AUTOSAR XML (schema 00050)
package /FCADT/ComponentTypes
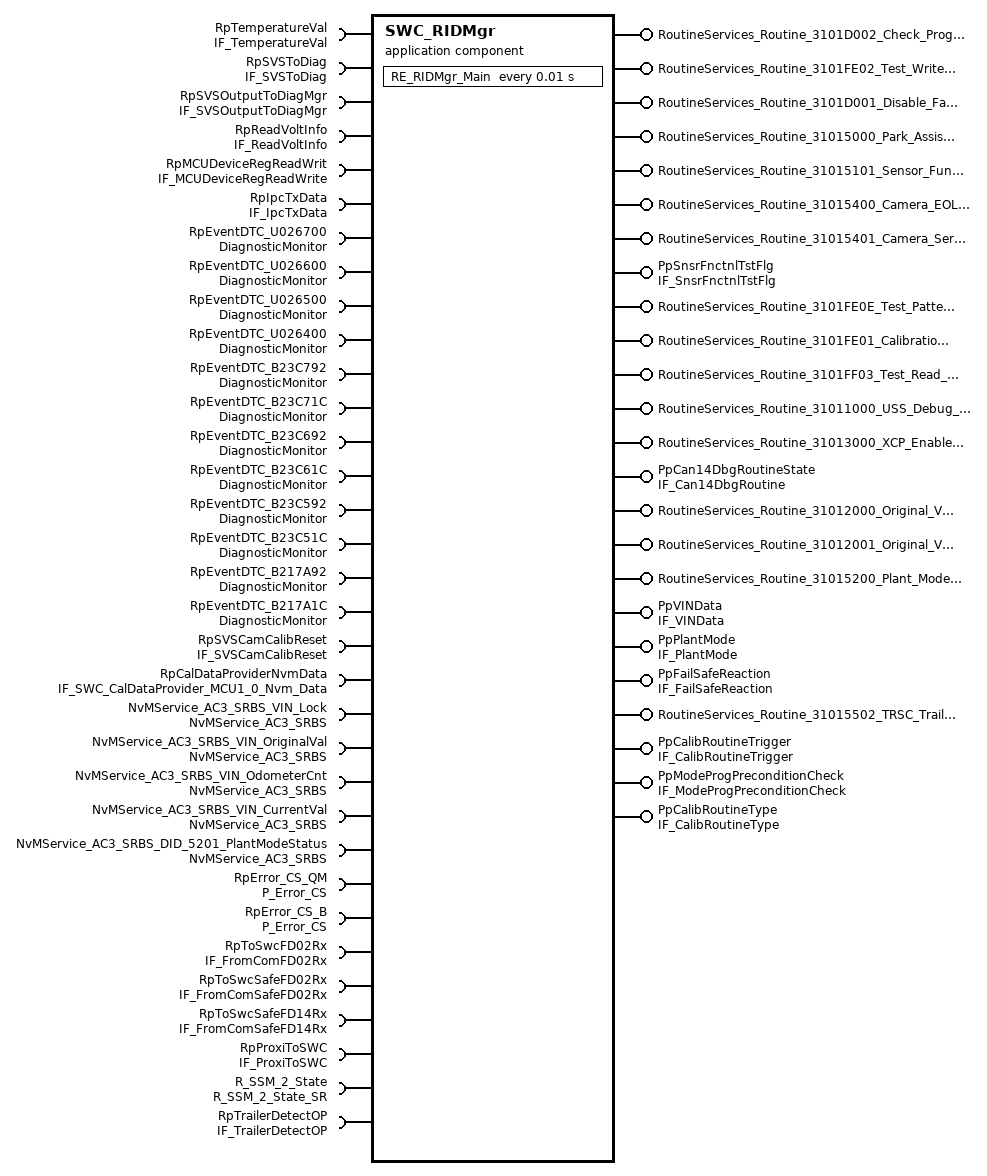
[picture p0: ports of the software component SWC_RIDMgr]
  application sw component type SWC_RIDMgr
    10 x provide port:
      RoutineServices_Routine_3101D002_Check_Programming_Preconditions_Start: server-com-spec{operation=Start, queue-length=1}, provided-interface=RoutineServices_Routine_3101D002_Check_Programming_Preconditions_Start
      RoutineServices_Routine_3101FE02_Test_Write_PMIC_Register_Start: server-com-spec{operation=Start, queue-length=1}, provided-interface=RoutineServices_Routine_3101FE02_Test_Write_PMIC_Register_Start
      RoutineServices_Routine_3101D001_Disable_Fail_safe_reaction_Start: provided-com-specs=[{operation=Start, queue-length=1}, {operation=Stop, queue-length=1}], provided-interface=RoutineServices_Routine_3101D001_Disable_Fail_safe_reaction_Start
      RoutineServices_Routine_31015000_Park_Assist_ON_OFF_State_Start: server-com-spec{operation=Start, queue-length=1}, provided-interface=RoutineServices_Routine_31015000_Park_Assist_ON_OFF_State_Start
      RoutineServices_Routine_31015101_Sensor_Functional_Test_Start: server-com-spec{operation=Start, queue-length=1}, provided-interface=RoutineServices_Routine_31015101_Sensor_Functional_Test_Start
      RoutineServices_Routine_31015400_Camera_EOL_Calibration_Start: provided-com-specs=[{operation=Start, queue-length=1}, {operation=RequestResults, queue-length=1}], provided-interface=RoutineServices_Routine_31015400_Camera_EOL_Calibration_Start
      RoutineServices_Routine_31015401_Camera_Service_Calibration_Start: provided-com-specs=[{operation=Start, queue-length=1}, {operation=RequestResults, queue-length=1}], provided-interface=RoutineServices_Routine_31015401_Camera_Service_Calibration_Start
      PpSnsrFnctnlTstFlg: nonqueued-sender-com-spec{data-element=SensorFunctionalTestFlag, init-value=constant-reference=init_SensorFunctionalTestFlag}, provided-interface=IF_SnsrFnctnlTstFlg
      RoutineServices_Routine_3101FE0E_Test_Pattern_Control_Start: provided-com-specs=[{operation=Stop, queue-length=1}, {operation=Start, queue-length=1}], provided-interface=RoutineServices_Routine_3101FE0E_Test_Pattern_Control_Start
      RoutineServices_Routine_3101FE01_Calibration_Data_Reset_Start: server-com-spec{operation=Start, queue-length=1}, provided-interface=RoutineServices_Routine_3101FE01_Calibration_Data_Reset_Start
    18 x require port:
      RpTemperatureVal: nonqueued-receiver-com-spec{data-element=GetTemperatureVal, filter=data-filter-type=ALWAYS}, required-interface=IF_TemperatureVal
      RpSVSToDiag: nonqueued-receiver-com-spec{data-element=SVSToDiag_t, filter=data-filter-type=ALWAYS}, required-interface=IF_SVSToDiag
      RpSVSOutputToDiagMgr: nonqueued-receiver-com-spec{data-element=TbSVS_e_SVSOutputToDiagMgrCamCalib_t, filter=data-filter-type=ALWAYS}, required-interface=IF_SVSOutputToDiagMgr
      RpReadVoltInfo: client-com-spec=GetVoltageInfo, required-interface=IF_ReadVoltInfo
      RpMCUDeviceRegReadWrit: required-com-specs=[MCUWriteDeviceReg, MCUReadDeviceRegData, MCUReadDeviceReg], required-interface=IF_MCUDeviceRegReadWrite
      RpIpcTxData: client-com-spec=IPC_Write_v, required-interface=IF_IpcTxData
      RpEventDTC_U026700: required-interface=DiagnosticMonitor
        required-com-specs:
          GetEventExtendedDataRecordEx
          GetEventFreezeFrameDataEx
          GetFaultDetectionCounter
          GetDTCOfEvent
          GetEventTested
          GetEventFailed
          GetEventStatus
          GetEventUdsStatus
          ResetEventDebounceStatus
          ResetEventStatus
          SetEventStatus
      RpEventDTC_U026600: required-interface=DiagnosticMonitor
        required-com-specs:
          GetEventExtendedDataRecordEx
          GetEventFreezeFrameDataEx
          GetFaultDetectionCounter
          GetDTCOfEvent
          GetEventTested
          GetEventFailed
          GetEventStatus
          GetEventUdsStatus
          ResetEventDebounceStatus
          ResetEventStatus
          SetEventStatus
      RpEventDTC_U026500: required-interface=DiagnosticMonitor
        required-com-specs:
          GetEventExtendedDataRecordEx
          GetEventFreezeFrameDataEx
          GetFaultDetectionCounter
          GetDTCOfEvent
          GetEventTested
          GetEventFailed
          GetEventStatus
          GetEventUdsStatus
          ResetEventDebounceStatus
          ResetEventStatus
          SetEventStatus
      RpEventDTC_U026400: required-interface=DiagnosticMonitor
        required-com-specs:
          GetEventExtendedDataRecordEx
          GetEventFreezeFrameDataEx
          GetFaultDetectionCounter
          GetDTCOfEvent
          GetEventTested
          GetEventFailed
          GetEventStatus
          GetEventUdsStatus
          ResetEventDebounceStatus
          ResetEventStatus
          SetEventStatus
      RpEventDTC_B23C792: required-interface=DiagnosticMonitor
        required-com-specs:
          GetEventExtendedDataRecordEx
          GetEventFreezeFrameDataEx
          GetFaultDetectionCounter
          GetDTCOfEvent
          GetEventTested
          GetEventFailed
          GetEventStatus
          GetEventUdsStatus
          ResetEventDebounceStatus
          ResetEventStatus
          SetEventStatus
      RpEventDTC_B23C71C: required-interface=DiagnosticMonitor
        required-com-specs:
          GetEventExtendedDataRecordEx
          GetEventFreezeFrameDataEx
          GetFaultDetectionCounter
          GetDTCOfEvent
          GetEventTested
          GetEventFailed
          GetEventStatus
          GetEventUdsStatus
          ResetEventDebounceStatus
          ResetEventStatus
          SetEventStatus
      RpEventDTC_B23C692: required-interface=DiagnosticMonitor
        required-com-specs:
          GetEventExtendedDataRecordEx
          GetEventFreezeFrameDataEx
          GetFaultDetectionCounter
          GetDTCOfEvent
          GetEventTested
          GetEventFailed
          GetEventStatus
          GetEventUdsStatus
          ResetEventDebounceStatus
          ResetEventStatus
          SetEventStatus
      RpEventDTC_B23C61C: required-interface=DiagnosticMonitor
        required-com-specs:
          GetEventExtendedDataRecordEx
          GetEventFreezeFrameDataEx
          GetFaultDetectionCounter
          GetDTCOfEvent
          GetEventTested
          GetEventFailed
          GetEventStatus
          GetEventUdsStatus
          ResetEventDebounceStatus
          ResetEventStatus
          SetEventStatus
      RpEventDTC_B23C592: required-interface=DiagnosticMonitor
        required-com-specs:
          GetEventExtendedDataRecordEx
          GetEventFreezeFrameDataEx
          GetFaultDetectionCounter
          GetDTCOfEvent
          GetEventTested
          GetEventFailed
          GetEventStatus
          GetEventUdsStatus
          ResetEventDebounceStatus
          ResetEventStatus
          SetEventStatus
      RpEventDTC_B23C51C: required-interface=DiagnosticMonitor
        required-com-specs:
          GetEventExtendedDataRecordEx
          GetEventFreezeFrameDataEx
          GetFaultDetectionCounter
          GetDTCOfEvent
          GetEventTested
          GetEventFailed
          GetEventStatus
          GetEventUdsStatus
          ResetEventDebounceStatus
          ResetEventStatus
          SetEventStatus
      RpEventDTC_B217A92: required-interface=DiagnosticMonitor
        required-com-specs:
          GetEventExtendedDataRecordEx
          GetEventFreezeFrameDataEx
          GetFaultDetectionCounter
          GetDTCOfEvent
          GetEventTested
          GetEventFailed
          GetEventStatus
          GetEventUdsStatus
          ResetEventDebounceStatus
          ResetEventStatus
          SetEventStatus
      RpEventDTC_B217A1C: required-interface=DiagnosticMonitor
        required-com-specs:
          GetEventExtendedDataRecordEx
          GetEventFreezeFrameDataEx
          GetFaultDetectionCounter
          GetDTCOfEvent
          GetEventTested
          GetEventFailed
          GetEventStatus
          GetEventUdsStatus
          ResetEventDebounceStatus
          ResetEventStatus
          SetEventStatus
    provide port RoutineServices_Routine_3101FF03_Test_Read_PMIC_Register_Start: server-com-spec{operation=Start, queue-length=1}, provided-interface=RoutineServices_Routine_3101FF03_Test_Read_PMIC_Register_Start
    require port RpSVSCamCalibReset: client-com-spec=WriteBlock, required-interface=IF_SVSCamCalibReset
    require port RpCalDataProviderNvmData: nonqueued-receiver-com-spec{data-element=CalData_mcu1_0, filter=data-filter-type=ALWAYS}, required-interface=IF_SWC_CalDataProvider_MCU1_0_Nvm_Data
    6 x provide port:
      RoutineServices_Routine_31011000_USS_Debug_Signals_Enable_Disable_Start: server-com-spec{operation=Start, queue-length=1}, provided-interface=RoutineServices_Routine_31011000_USS_Debug_Signals_Enable_Disable_Start
      RoutineServices_Routine_31013000_XCP_Enable_Disable_Start: server-com-spec{operation=Start, queue-length=1}, provided-interface=RoutineServices_Routine_31013000_XCP_Enable_Disable_Start
      PpCan14DbgRoutineState: nonqueued-sender-com-spec{data-element=Can14DbgRoutine, init-value=0}, provided-interface=IF_Can14DbgRoutine
      RoutineServices_Routine_31012000_Original_VIN_Lock: server-com-spec{operation=Start, queue-length=1}, provided-interface=RoutineServices_Routine_31012000_Original_VIN_Lock
      RoutineServices_Routine_31012001_Original_VIN_Unlock: server-com-spec{operation=Start, queue-length=1}, provided-interface=RoutineServices_Routine_31012001_Original_VIN_Unlock
      RoutineServices_Routine_31015200_Plant_Mode_Routine_Start: provided-com-specs=[{operation=RequestResults, queue-length=1}, {operation=Start, queue-length=1}], provided-interface=RoutineServices_Routine_31015200_Plant_Mode_Routine_Start
    5 x require port, all with required-com-specs=[WriteBlock, SetRamBlockStatus, ReadBlock, InvalidateNvBlock, GetErrorStatus, EraseBlock], required-interface=NvMService_AC3_SRBS:
      NvMService_AC3_SRBS_VIN_Lock
      NvMService_AC3_SRBS_VIN_OriginalVal
      NvMService_AC3_SRBS_VIN_OdometerCnt
      NvMService_AC3_SRBS_VIN_CurrentVal
      NvMService_AC3_SRBS_DID_5201_PlantModeStatus
    provide port PpVINData: provided-com-specs=[VINOriginalData, VINCurrentData, VINOdoCounter, VINLockStatus], provided-interface=IF_VINData
    require port RpError_CS_QM: client-com-spec=ReportErrorStatus1_0_QM, required-interface=P_Error_CS
    require port RpError_CS_B: client-com-spec=ReportErrorStatus1_0_B, required-interface=P_Error_CS
    provide port PpPlantMode: nonqueued-sender-com-spec{data-element=Status, init-value=0}, provided-interface=IF_PlantMode
    require port RpToSwcFD02Rx: required-interface=IF_FromComFD02Rx
      required-com-specs:
        data-element=Altitude_RMSE_C2, filter=data-filter-type=ALWAYS, init-value=255
        data-element=Battery_Volt_1, filter=data-filter-type=ALWAYS, init-value=0
        data-element=BSM_THA_Brk_Resp, filter=data-filter-type=ALWAYS, init-value=0
        data-element=CurrentCanNMState_FD01_BCM, filter=data-filter-type=ALWAYS, init-value=0
        data-element=CurrentCanNMState_FD01_SGW, filter=data-filter-type=ALWAYS, init-value=0
        data-element=CurrentCanNMState_FD02_BCM, filter=data-filter-type=ALWAYS, init-value=0
        data-element=CurrentCanNMState_FD02_BSM2, filter=data-filter-type=ALWAYS, init-value=0
        data-element=CurrentCanNMState_FD02_CADM2, filter=data-filter-type=ALWAYS, init-value=0
        data-element=CurrentCanNMState_FD02_EPS, filter=data-filter-type=ALWAYS, init-value=0
        data-element=CurrentCanNMState_FD02_ORC, filter=data-filter-type=ALWAYS, init-value=0
        data-element=CurrentCanNMState_FD02_SGW, filter=data-filter-type=ALWAYS, init-value=0
        data-element=CurrentCanNMState_FD02_TRLR_REV, filter=data-filter-type=ALWAYS, init-value=0
        data-element=CurrentCanNMState_FD03_BCM, filter=data-filter-type=ALWAYS, init-value=0
        data-element=CurrentCanNMState_FD03_SGW, filter=data-filter-type=ALWAYS, init-value=0
        data-element=CurrentCanNMState_FD04_BCM, filter=data-filter-type=ALWAYS, init-value=0
        data-element=CurrentCanNMState_FD08_SGW, filter=data-filter-type=ALWAYS, init-value=0
        data-element=CurrentCanNMState_FD11_SGW, filter=data-filter-type=ALWAYS, init-value=0
        data-element=CurrentFailSts_FD01_BCM, filter=data-filter-type=ALWAYS, init-value=0
        data-element=CurrentFailSts_FD01_SGW, filter=data-filter-type=ALWAYS, init-value=0
        data-element=CurrentFailSts_FD02_BCM, filter=data-filter-type=ALWAYS, init-value=0
        data-element=CurrentFailSts_FD02_BSM2, filter=data-filter-type=ALWAYS, init-value=0
        data-element=CurrentFailSts_FD02_CADM2, filter=data-filter-type=ALWAYS, init-value=0
        data-element=CurrentFailSts_FD02_EPS, filter=data-filter-type=ALWAYS, init-value=0
        data-element=CurrentFailSts_FD02_ORC, filter=data-filter-type=ALWAYS, init-value=0
        data-element=CurrentFailSts_FD02_SGW, filter=data-filter-type=ALWAYS, init-value=0
        data-element=CurrentFailSts_FD02_TRLR_REV, filter=data-filter-type=ALWAYS, init-value=0
        data-element=CurrentFailSts_FD03_BCM, filter=data-filter-type=ALWAYS, init-value=0
        data-element=CurrentFailSts_FD03_SGW, filter=data-filter-type=ALWAYS, init-value=0
        data-element=CurrentFailSts_FD04_BCM, filter=data-filter-type=ALWAYS, init-value=0
        data-element=CurrentFailSts_FD08_SGW, filter=data-filter-type=ALWAYS, init-value=0
        data-element=CurrentFailSts_FD11_SGW, filter=data-filter-type=ALWAYS, init-value=0
        data-element=DeltaTimestamp_IMUdata, filter=data-filter-type=ALWAYS, init-value=255
        data-element=DES_FD01_BCM, filter=data-filter-type=ALWAYS, init-value=0
        data-element=DES_FD01_SGW, filter=data-filter-type=ALWAYS, init-value=0
        data-element=DES_FD02_BCM, filter=data-filter-type=ALWAYS, init-value=0
        data-element=DES_FD02_BSM2, filter=data-filter-type=ALWAYS, init-value=0
        data-element=DES_FD02_CADM2, filter=data-filter-type=ALWAYS, init-value=0
        data-element=DES_FD02_EPS, filter=data-filter-type=ALWAYS, init-value=0
        data-element=DES_FD02_ORC, filter=data-filter-type=ALWAYS, init-value=0
        data-element=DES_FD02_SGW, filter=data-filter-type=ALWAYS, init-value=0
        data-element=DES_FD02_TRLR_REV, filter=data-filter-type=ALWAYS, init-value=0
        data-element=DES_FD03_BCM, filter=data-filter-type=ALWAYS, init-value=0
        data-element=DES_FD03_SGW, filter=data-filter-type=ALWAYS, init-value=0
        data-element=DES_FD04_BCM, filter=data-filter-type=ALWAYS, init-value=0
        data-element=DES_FD08_SGW, filter=data-filter-type=ALWAYS, init-value=0
        data-element=DES_FD11_SGW, filter=data-filter-type=ALWAYS, init-value=0
        data-element=Digit_{01..11}, filter=data-filter-type=ALWAYS, init-value=0
        data-element=EOL_FD01_BCM, filter=data-filter-type=ALWAYS, init-value=0
        data-element=EOL_FD01_SGW, filter=data-filter-type=ALWAYS, init-value=0
        data-element=EOL_FD02_BCM, filter=data-filter-type=ALWAYS, init-value=0
        data-element=EOL_FD02_BSM2, filter=data-filter-type=ALWAYS, init-value=0
        data-element=EOL_FD02_CADM2, filter=data-filter-type=ALWAYS, init-value=0
        data-element=EOL_FD02_EPS, filter=data-filter-type=ALWAYS, init-value=0
        data-element=EOL_FD02_ORC, filter=data-filter-type=ALWAYS, init-value=0
        data-element=EOL_FD02_SGW, filter=data-filter-type=ALWAYS, init-value=0
        data-element=EOL_FD02_TRLR_REV, filter=data-filter-type=ALWAYS, init-value=0
        data-element=EOL_FD03_BCM, filter=data-filter-type=ALWAYS, init-value=0
        data-element=EOL_FD03_SGW, filter=data-filter-type=ALWAYS, init-value=0
        data-element=EOL_FD04_BCM, filter=data-filter-type=ALWAYS, init-value=0
        data-element=EOL_FD08_SGW, filter=data-filter-type=ALWAYS, init-value=0
        data-element=EOL_FD11_SGW, filter=data-filter-type=ALWAYS, init-value=0
        data-element=EPBSts, filter=data-filter-type=ALWAYS, init-value=0
        data-element=GenericFailSts_FD01_BCM, filter=data-filter-type=ALWAYS, init-value=0
        data-element=GenericFailSts_FD01_SGW, filter=data-filter-type=ALWAYS, init-value=0
        data-element=GenericFailSts_FD02_BCM, filter=data-filter-type=ALWAYS, init-value=0
        data-element=GenericFailSts_FD02_BSM2, filter=data-filter-type=ALWAYS, init-value=0
        data-element=GenericFailSts_FD02_CADM2, filter=data-filter-type=ALWAYS, init-value=0
        data-element=GenericFailSts_FD02_EPS, filter=data-filter-type=ALWAYS, init-value=0
        data-element=GenericFailSts_FD02_ORC, filter=data-filter-type=ALWAYS, init-value=0
        data-element=GenericFailSts_FD02_SGW, filter=data-filter-type=ALWAYS, init-value=0
        data-element=GenericFailSts_FD02_TRLR_REV, filter=data-filter-type=ALWAYS, init-value=0
        data-element=GenericFailSts_FD03_BCM, filter=data-filter-type=ALWAYS, init-value=0
        data-element=GenericFailSts_FD03_SGW, filter=data-filter-type=ALWAYS, init-value=0
        data-element=GenericFailSts_FD04_BCM, filter=data-filter-type=ALWAYS, init-value=0
        data-element=GenericFailSts_FD08_SGW, filter=data-filter-type=ALWAYS, init-value=0
        data-element=GenericFailSts_FD11_SGW, filter=data-filter-type=ALWAYS, init-value=0
        data-element=Heading_Angle_C2, filter=data-filter-type=ALWAYS, init-value=65535
        data-element=IgnitionOnCounter, filter=data-filter-type=ALWAYS, init-value=0
        data-element=LatAcceleration_C2, filter=data-filter-type=ALWAYS, init-value=4095
        data-element=LatAccelerationOffset_BSM, filter=data-filter-type=ALWAYS, init-value=255
        data-element=Latitude_RMSE_C2, filter=data-filter-type=ALWAYS, init-value=255
        data-element=LHF_FastPulseCounter, filter=data-filter-type=ALWAYS, init-value=0
        data-element=LHF_Spin, filter=data-filter-type=ALWAYS, init-value=0
        data-element=LHFWheelSpeed, filter=data-filter-type=ALWAYS, init-value=0
        data-element=LHR_FastPulseCounter, filter=data-filter-type=ALWAYS, init-value=0
        data-element=LHR_Spin, filter=data-filter-type=ALWAYS, init-value=0
        data-element=LHRWheelSpeed, filter=data-filter-type=ALWAYS, init-value=0
        data-element=LongAcceleration_C2, filter=data-filter-type=ALWAYS, init-value=4095
        data-element=LongAccelerationOffset_BSM, filter=data-filter-type=ALWAYS, init-value=255
        data-element=Longitude_RMSE_C2, filter=data-filter-type=ALWAYS, init-value=255
        data-element=OperationalModeSts, filter=data-filter-type=ALWAYS, init-value=0
        data-element=Pitch_RMSE_C2, filter=data-filter-type=ALWAYS, init-value=255
        data-element=PitchRate_C2, filter=data-filter-type=ALWAYS, init-value=4095
        data-element=PreviousCanNMState_FD01_BCM, filter=data-filter-type=ALWAYS, init-value=0
        data-element=PreviousCanNMState_FD01_SGW, filter=data-filter-type=ALWAYS, init-value=0
        data-element=PreviousCanNMState_FD02_BCM, filter=data-filter-type=ALWAYS, init-value=0
        data-element=PreviousCanNMState_FD02_BSM2, filter=data-filter-type=ALWAYS, init-value=0
        data-element=PreviousCanNMState_FD02_CADM2, filter=data-filter-type=ALWAYS, init-value=0
        data-element=PreviousCanNMState_FD02_EPS, filter=data-filter-type=ALWAYS, init-value=0
        data-element=PreviousCanNMState_FD02_ORC, filter=data-filter-type=ALWAYS, init-value=0
        data-element=PreviousCanNMState_FD02_SGW, filter=data-filter-type=ALWAYS, init-value=0
        data-element=PreviousCanNMState_FD02_TRLR_REV, filter=data-filter-type=ALWAYS, init-value=0
        data-element=PreviousCanNMState_FD03_BCM, filter=data-filter-type=ALWAYS, init-value=0
        data-element=PreviousCanNMState_FD03_SGW, filter=data-filter-type=ALWAYS, init-value=0
        data-element=PreviousCanNMState_FD04_BCM, filter=data-filter-type=ALWAYS, init-value=0
        data-element=PreviousCanNMState_FD08_SGW, filter=data-filter-type=ALWAYS, init-value=0
        data-element=PreviousCanNMState_FD11_SGW, filter=data-filter-type=ALWAYS, init-value=0
        data-element=REF_VEH_SPEED, filter=data-filter-type=ALWAYS, init-value=1023
        data-element=RemStActvSts, filter=data-filter-type=ALWAYS, init-value=0
        data-element=RHF_FastPulseCounter, filter=data-filter-type=ALWAYS, init-value=0
        data-element=RHF_Spin, filter=data-filter-type=ALWAYS, init-value=0
        data-element=RHFWheelSpeed, filter=data-filter-type=ALWAYS, init-value=0
        data-element=RHR_FastPulseCounter, filter=data-filter-type=ALWAYS, init-value=0
        data-element=RHR_Spin, filter=data-filter-type=ALWAYS, init-value=0
        data-element=RHRWheelSpeed, filter=data-filter-type=ALWAYS, init-value=0
        data-element=Roll_RMSE_C2, filter=data-filter-type=ALWAYS, init-value=255
        data-element=RollRate_C2, filter=data-filter-type=ALWAYS, init-value=4095
        data-element=SBR1RowDriverSeatSts, filter=data-filter-type=ALWAYS, init-value=3
        data-element=StayActiveSource_FD01_BCM, filter=data-filter-type=ALWAYS, init-value=0
        data-element=StayActiveSource_FD01_SGW, filter=data-filter-type=ALWAYS, init-value=0
        data-element=StayActiveSource_FD02_BCM, filter=data-filter-type=ALWAYS, init-value=0
        data-element=StayActiveSource_FD02_BSM2, filter=data-filter-type=ALWAYS, init-value=0
        data-element=StayActiveSource_FD02_CADM2, filter=data-filter-type=ALWAYS, init-value=0
        data-element=StayActiveSource_FD02_EPS, filter=data-filter-type=ALWAYS, init-value=0
        data-element=StayActiveSource_FD02_ORC, filter=data-filter-type=ALWAYS, init-value=0
        data-element=StayActiveSource_FD02_SGW, filter=data-filter-type=ALWAYS, init-value=0
        data-element=StayActiveSource_FD02_TRLR_REV, filter=data-filter-type=ALWAYS, init-value=0
        data-element=StayActiveSource_FD03_BCM, filter=data-filter-type=ALWAYS, init-value=0
        data-element=StayActiveSource_FD03_SGW, filter=data-filter-type=ALWAYS, init-value=0
        data-element=StayActiveSource_FD04_BCM, filter=data-filter-type=ALWAYS, init-value=0
        data-element=StayActiveSource_FD08_SGW, filter=data-filter-type=ALWAYS, init-value=0
        data-element=StayActiveSource_FD11_SGW, filter=data-filter-type=ALWAYS, init-value=0
        data-element=TotalOdometer, filter=data-filter-type=ALWAYS, init-value=0
        data-element=TRSC_CenterBtn_Sts, filter=data-filter-type=ALWAYS, init-value=0
        data-element=TRSC_EnableBtn_Sts, filter=data-filter-type=ALWAYS, init-value=0
        data-element=TRSC_RawKnob, filter=data-filter-type=ALWAYS, init-value=0
        data-element=TurnIndicatorSts, filter=data-filter-type=ALWAYS, init-value=0
        data-element=VehicleStandStillSts, filter=data-filter-type=ALWAYS, init-value=1
        data-element=VerticalAcceleration_C2, filter=data-filter-type=ALWAYS, init-value=4095
        data-element=WakeupSource_FD01_ADCM, filter=data-filter-type=ALWAYS, init-value=0
        data-element=WakeupSource_FD01_BCM, filter=data-filter-type=ALWAYS, init-value=0
        data-element=WakeupSource_FD01_SGW, filter=data-filter-type=ALWAYS, init-value=0
        data-element=WakeupSource_FD02_BCM, filter=data-filter-type=ALWAYS, init-value=0
        data-element=WakeupSource_FD02_BSM2, filter=data-filter-type=ALWAYS, init-value=0
        data-element=WakeupSource_FD02_CADM2, filter=data-filter-type=ALWAYS, init-value=0
        data-element=WakeupSource_FD02_EPS, filter=data-filter-type=ALWAYS, init-value=0
        data-element=WakeupSource_FD02_ORC, filter=data-filter-type=ALWAYS, init-value=0
        data-element=WakeupSource_FD02_SGW, filter=data-filter-type=ALWAYS, init-value=0
        data-element=WakeupSource_FD02_TRLR_REV, filter=data-filter-type=ALWAYS, init-value=0
        data-element=WakeupSource_FD03_BCM, filter=data-filter-type=ALWAYS, init-value=0
        data-element=WakeupSource_FD03_SGW, filter=data-filter-type=ALWAYS, init-value=0
        data-element=WakeupSource_FD04_BCM, filter=data-filter-type=ALWAYS, init-value=0
        data-element=WakeupSource_FD08_SGW, filter=data-filter-type=ALWAYS, init-value=0
        data-element=WakeupSource_FD11_SGW, filter=data-filter-type=ALWAYS, init-value=0
        data-element=YawRate_C2, filter=data-filter-type=ALWAYS, init-value=4095
        data-element=YawRate_RMSE_C2, filter=data-filter-type=ALWAYS, init-value=255
    require port RpToSwcSafeFD02Rx: required-interface=IF_FromComSafeFD02Rx
      required-com-specs:
        data-element=Active_Park_Mode, filter=data-filter-type=ALWAYS, init-value=0
        data-element=Active_Park_Prox_Chime, filter=data-filter-type=ALWAYS, init-value=0
        data-element=APARequestSts, filter=data-filter-type=ALWAYS, init-value=0
        data-element=Backup_Cam_Delay, filter=data-filter-type=ALWAYS, init-value=0
        data-element=Brk_Stat, filter=data-filter-type=ALWAYS, init-value=0
        data-element=CmdIgnSts, filter=data-filter-type=ALWAYS, init-value=0
        data-element=DriverDoorSts, filter=data-filter-type=ALWAYS, init-value=0
        data-element=DynamicGrid, filter=data-filter-type=ALWAYS, init-value=1
        data-element=ExternalTemperature, filter=data-filter-type=ALWAYS, init-value=0
        data-element=FT_PAMRequestSts, filter=data-filter-type=ALWAYS, init-value=0
        data-element=Fwrd_Cam_Guidelines, filter=data-filter-type=ALWAYS, init-value=0
        data-element=GearEngaged, filter=data-filter-type=ALWAYS, init-value=0
        data-element=HAS_Status_C2, filter=data-filter-type=ALWAYS, init-value=0
        data-element=LanguageSelection, filter=data-filter-type=ALWAYS, init-value=0
        data-element=LatAcceleration_BSM, filter=data-filter-type=ALWAYS, init-value=4095
        data-element=LHRDoorSts, filter=data-filter-type=ALWAYS, init-value=0
        data-element=LongAcceleration_BSM, filter=data-filter-type=ALWAYS, init-value=4095
        data-element=LwsAngle, filter=data-filter-type=ALWAYS, init-value=0
        data-element=LwsAngleType, filter=data-filter-type=ALWAYS, init-value=0
        data-element=LwsSpeed, filter=data-filter-type=ALWAYS, init-value=0
        data-element=MRM_STATUS_C2, filter=data-filter-type=ALWAYS, init-value=0
        data-element=PamChimeVolumeFront, filter=data-filter-type=ALWAYS, init-value=1
        data-element=PamChimeVolumeRear, filter=data-filter-type=ALWAYS, init-value=1
        data-element=PAMRequestSts, filter=data-filter-type=ALWAYS, init-value=0
        data-element=PsngrDoorSts, filter=data-filter-type=ALWAYS, init-value=0
        data-element=Rear_Brk_Asst, filter=data-filter-type=ALWAYS, init-value=0
        data-element=RHatchSts, filter=data-filter-type=ALWAYS, init-value=0
        data-element=RHRDoorSts, filter=data-filter-type=ALWAYS, init-value=0
        data-element=ShiftLeverPosition, filter=data-filter-type=ALWAYS, init-value=0
        data-element=SVC_Guidelines, filter=data-filter-type=ALWAYS, init-value=0
        data-element=TargetGear, filter=data-filter-type=ALWAYS, init-value=15
        data-element=TCASERANGESTATUS, filter=data-filter-type=ALWAYS, init-value=0
        data-element=TGW_CAMERA_DISP_STAT, filter=data-filter-type=ALWAYS, init-value=0
        data-element=TrailerConnectionSts, filter=data-filter-type=ALWAYS, init-value=0
        data-element=TRANS_ADAS_Inhibit, filter=data-filter-type=ALWAYS, init-value=0
        data-element=TransmissionSailingSts, filter=data-filter-type=ALWAYS, init-value=0
        data-element=VehicleSpeedVSOSig, filter=data-filter-type=ALWAYS, init-value=0
        data-element=YawRate_BSM, filter=data-filter-type=ALWAYS, init-value=4095
        data-element=VIN_MSG, filter=data-filter-type=ALWAYS
        data-element=VIN_DATA, filter=data-filter-type=ALWAYS
        data-element=RR_Lvl_Adj, filter=data-filter-type=ALWAYS
        data-element=RR_Lvl, filter=data-filter-type=ALWAYS
        data-element=RL_Lvl_Adj, filter=data-filter-type=ALWAYS
        data-element=RL_Lvl, filter=data-filter-type=ALWAYS
        data-element=HU_TRSC_EnableBtn_Sts, filter=data-filter-type=ALWAYS
        data-element=GearEngagedForDisplay, filter=data-filter-type=ALWAYS
        data-element=FR_Lvl_Adj, filter=data-filter-type=ALWAYS
        data-element=FR_Lvl, filter=data-filter-type=ALWAYS
        data-element=FL_Lvl_Adj, filter=data-filter-type=ALWAYS
        data-element=FL_Lvl, filter=data-filter-type=ALWAYS
        data-element=ESS_ENG_ST_W, filter=data-filter-type=ALWAYS
        data-element=EngineSts_W, filter=data-filter-type=ALWAYS
        data-element=ECM_TRSC_Resp, filter=data-filter-type=ALWAYS
        data-element=ECM_THA_Resp, filter=data-filter-type=ALWAYS
        data-element=ASCM_SysFail, filter=data-filter-type=ALWAYS
        data-element=ASCM_Stat, filter=data-filter-type=ALWAYS
        data-element=PdlPosActual, filter=data-filter-type=ALWAYS
        data-element=THA_SteeringTouchStat, filter=data-filter-type=ALWAYS
        data-element=EPS_THA_SteeringTorqueResp, filter=data-filter-type=ALWAYS
        data-element=EPS_THA_DriverTorqueOverride, filter=data-filter-type=ALWAYS
        data-element=EPS_SteeringTouq_Resp, filter=data-filter-type=ALWAYS
        data-element=EPS_SteeringTouchStat, filter=data-filter-type=ALWAYS
        data-element=ShiftLeverPositionReq, filter=data-filter-type=ALWAYS
        data-element=Shifter_ADAS_Inhibit, filter=data-filter-type=ALWAYS
        data-element=ITBM_TrlrStat, filter=data-filter-type=ALWAYS
        data-element=CM_TCH_Y_COORD, filter=data-filter-type=ALWAYS
        data-element=CM_TCH_X_COORD, filter=data-filter-type=ALWAYS
        data-element=CM_TCH_STAT, filter=data-filter-type=ALWAYS
        data-element=CameraDisplaySts2, filter=data-filter-type=ALWAYS
    require port RpToSwcSafeFD14Rx: required-interface=IF_FromComSafeFD14Rx
      required-com-specs:
        data-element=FD14_ACC_Systemsts, filter=data-filter-type=ALWAYS, init-value=0
        data-element=FD14_Brk_Stat, filter=data-filter-type=ALWAYS, init-value=0
        data-element=FD14_BrkPdl_Stat, filter=data-filter-type=ALWAYS, init-value=3
        data-element=FD14_BrkTrq, filter=data-filter-type=ALWAYS, init-value=32767
        data-element=FD14_BrkTrq_Driver, filter=data-filter-type=ALWAYS, init-value=32767
        data-element=FD14_BSM_THA_Brk_Resp, filter=data-filter-type=ALWAYS, init-value=0
        data-element=FD14_EPBSts, filter=data-filter-type=ALWAYS, init-value=0
        data-element=FD14_EPS_HandsOnRecognition, filter=data-filter-type=ALWAYS, init-value=0
        data-element=FD14_ESC_TRSC_Brk_Resp, filter=data-filter-type=ALWAYS, init-value=0
        data-element=FD14_ExternalBrkRequestsDisabled, filter=data-filter-type=ALWAYS, init-value=0
        data-element=FD14_HAS_Status, filter=data-filter-type=ALWAYS, init-value=0
        data-element=FD14_LatAcceleration_BSM, filter=data-filter-type=ALWAYS, init-value=4095
        data-element=FD14_LatAccelerationFailSts_BSM, filter=data-filter-type=ALWAYS, init-value=0
        data-element=FD14_LatAccelerationOffset_BSM, filter=data-filter-type=ALWAYS, init-value=255
        data-element=FD14_LHF_FastPulseCounter, filter=data-filter-type=ALWAYS, init-value=0
        data-element=FD14_LHF_Spin, filter=data-filter-type=ALWAYS, init-value=0
        data-element=FD14_LHF_WheelSensorFailSts, filter=data-filter-type=ALWAYS, init-value=0
        data-element=FD14_LHFWheelSpeed, filter=data-filter-type=ALWAYS, init-value=0
        data-element=FD14_LHR_FastPulseCounter, filter=data-filter-type=ALWAYS, init-value=0
        data-element=FD14_LHR_Spin, filter=data-filter-type=ALWAYS, init-value=0
        data-element=FD14_LHR_WheelSensorFailSts, filter=data-filter-type=ALWAYS, init-value=0
        data-element=FD14_LHRWheelSpeed, filter=data-filter-type=ALWAYS, init-value=0
        data-element=FD14_LongAcceleration_BSM, filter=data-filter-type=ALWAYS, init-value=4095
        data-element=FD14_LongAccelerationFailSts_BSM, filter=data-filter-type=ALWAYS, init-value=0
        data-element=FD14_LongAccelerationOffset_BSM, filter=data-filter-type=ALWAYS, init-value=255
        data-element=FD14_LwsAngle, filter=data-filter-type=ALWAYS, init-value=0
        data-element=FD14_LwsAngleType, filter=data-filter-type=ALWAYS, init-value=0
        data-element=FD14_LwsSpeed, filter=data-filter-type=ALWAYS, init-value=0
        data-element=FD14_PAM_Brk_Rq_RspSts, filter=data-filter-type=ALWAYS, init-value=0
        data-element=FD14_ParkingGearShiftReq_BSM, filter=data-filter-type=ALWAYS, init-value=0
        data-element=FD14_ParkingInterventionSts, filter=data-filter-type=ALWAYS, init-value=0
        data-element=FD14_REF_VEH_SPEED, filter=data-filter-type=ALWAYS, init-value=1023
        data-element=FD14_RHF_FastPulseCounter, filter=data-filter-type=ALWAYS, init-value=0
        data-element=FD14_RHF_Spin, filter=data-filter-type=ALWAYS, init-value=0
        data-element=FD14_RHF_WheelSensorFailSts, filter=data-filter-type=ALWAYS, init-value=0
        data-element=FD14_RHFWheelSpeed, filter=data-filter-type=ALWAYS, init-value=0
        data-element=FD14_RHR_FastPulseCounter, filter=data-filter-type=ALWAYS, init-value=0
        data-element=FD14_RHR_Spin, filter=data-filter-type=ALWAYS, init-value=0
        data-element=FD14_RHR_WheelSensorFailSts, filter=data-filter-type=ALWAYS, init-value=0
        data-element=FD14_RHRWheelSpeed, filter=data-filter-type=ALWAYS, init-value=0
        data-element=FD14_Slope, filter=data-filter-type=ALWAYS, init-value=0
        data-element=FD14_SPM_Lat_Ctrl_ResponseSts, filter=data-filter-type=ALWAYS, init-value=0
        data-element=FD14_Steering_Column_Torque, filter=data-filter-type=ALWAYS, init-value=0
        data-element=FD14_VehicleSpeedVSOSig, filter=data-filter-type=ALWAYS, init-value=0
        data-element=FD14_VehicleSpeedVSOSig_B2, filter=data-filter-type=ALWAYS, init-value=0
        data-element=FD14_VehicleStandStillSts, filter=data-filter-type=ALWAYS, init-value=1
        data-element=FD14_YawRate_BSM, filter=data-filter-type=ALWAYS, init-value=4095
        data-element=FD14_YawRateFailSts_BSM, filter=data-filter-type=ALWAYS, init-value=0
        data-element=FD14_ESS_ENG_ST_W, filter=data-filter-type=ALWAYS
        data-element=FD14_EngineSts_W, filter=data-filter-type=ALWAYS
        data-element=FD14_ECM_TRSC_Resp, filter=data-filter-type=ALWAYS
        data-element=FD14_ECM_THA_Resp, filter=data-filter-type=ALWAYS
        data-element=FD14_PdlPosActual, filter=data-filter-type=ALWAYS
        data-element=FD14_THA_SteeringTouchStat, filter=data-filter-type=ALWAYS
        data-element=FD14_EPS_THA_SteeringTorqueResp, filter=data-filter-type=ALWAYS
        data-element=FD14_EPS_THA_DriverTorqueOverride, filter=data-filter-type=ALWAYS
        data-element=FD14_EPS_SteeringTouq_Resp, filter=data-filter-type=ALWAYS
        data-element=FD14_EPS_SteeringTouchStat, filter=data-filter-type=ALWAYS
    provide port PpFailSafeReaction: nonqueued-sender-com-spec{data-element=State, init-value=0}, provided-interface=IF_FailSafeReaction
    require port RpProxiToSWC: required-interface=IF_ProxiToSWC
      required-com-specs:
        data-element=TyreSz_u16, filter=data-filter-type=ALWAYS
        data-element=SurroundViewCam_u8, filter=data-filter-type=ALWAYS
        data-element=Fullautomaticparking, filter=data-filter-type=ALWAYS
        data-element=PRX_CanNod27_b
        data-element=Parkwithstop_u8
        data-element=Trailerhitchassist_u8
        data-element=PAMConfig_u8
        data-element=Pamtuningset
    require port R_SSM_2_State: required-interface=R_SSM_2_State_SR
      required-com-specs:
        data-element=State_2_1, filter=data-filter-type=ALWAYS, init-value=fields=[CoreStatus:0, LocalAppStatus:20 x 0]
        data-element=State_2_0, filter=data-filter-type=ALWAYS, init-value=fields=[CoreStatus:0, LocalAppStatus:20 x 0]
    provide port RoutineServices_Routine_31015502_TRSC_Trailer_Calibration_Memory_Clear_Start: provided-com-specs=[{operation=RequestResults, queue-length=1}, {operation=Start, queue-length=1}], provided-interface=RoutineServices_Routine_31015502_TRSC_Trailer_Calibration_Memory_Clear_Start
    require port RpTrailerDetectOP: nonqueued-receiver-com-spec{data-element=TrailerDetection_Output_DID_t, filter=data-filter-type=ALWAYS}, required-interface=IF_TrailerDetectOP
    provide port PpCalibRoutineTrigger: nonqueued-sender-com-spec{data-element=routine_b, init-value=0}, provided-interface=IF_CalibRoutineTrigger
    provide port PpModeProgPreconditionCheck: mode-switch-sender-com-spec{mode-group=ModeProgPreconditionCheck, queue-length=1}, provided-interface=IF_ModeProgPreconditionCheck
    provide port PpCalibRoutineType: nonqueued-sender-com-spec{data-element=value, init-value=0}, provided-interface=IF_CalibRoutineType
    behavior SWC_RIDMgr_InternalBehavior: data-type-mapping=DataTypeMappings_DEV, handle-termination-and-restart=NO-SUPPORT
      ar-typed-per-instance-memorys:
        5 x data, all with sw-calibration-access=READ-ONLY:
          VIN_Lock_MirrorBlock: type=uint8
          DID_5201_PlantModeStatus_MirrorBlock: type=uint8
          VIN_CurrentVal_MirrorBlock: type=VINlData_Arr
          VIN_OdometerCnt_MirrorBlock: type=uint8
          VIN_OriginalVal_MirrorBlock: type=VINlData_Arr
      init event InitEvent: start-on-event=RE_RIDMgrr_Init
      timing event TMT_RE_RIDMgr_Main: start-on-event=RE_RIDMgr_Main, period=0.01
      22 x operation invoked event:
        OIT_RoutineServices_Routine_31015401_Camera_Service_Calibration_Start_RequestResults_RoutineServices_Routine_31015401_Ca69CD58AC: start-on-event=RoutineServices_Routine_31015401_Camera_Service_Calibration_Start_RequestResults, operation=RoutineServices_Routine_31015401_Camera_Service_Calibration_Start.RequestResults
        OIT_RoutineServices_Routine_31015401_Camera_Service_Calibration_Start_Start_RoutineServices_Routine_31015401_Camera_Serv0FB43942: start-on-event=RoutineServices_Routine_31015401_Camera_Service_Calibration_Start_Start, operation=RoutineServices_Routine_31015401_Camera_Service_Calibration_Start.Start
        OIT_RoutineServices_Routine_3101FE02_Test_Write_PMIC_Register_Start_Start_RoutineServices_Routine_3101FE02_Test_Write_PMC3ED047F: start-on-event=RoutineServices_Routine_3101FE02_Test_Write_PMIC_Register_Start_Start, operation=RoutineServices_Routine_3101FE02_Test_Write_PMIC_Register_Start.Start
        OIT_RoutineServices_Routine_3101D002_Check_Programming_Preconditions_Start_Start_RoutineServices_Routine_3101D002_Check_C7D56839: start-on-event=RoutineServices_Routine_3101D002_Check_Programming_Preconditions_Start_Start, operation=RoutineServices_Routine_3101D002_Check_Programming_Preconditions_Start.Start
        OIT_RoutineServices_Routine_3101FE01_Calibration_Data_Reset_Start_Start_RoutineServices_Routine_3101FE01_Calibration_Dat507DEF71: start-on-event=RoutineServices_Routine_3101FE01_Calibration_Data_Reset_Start_Start, operation=RoutineServices_Routine_3101FE01_Calibration_Data_Reset_Start.Start
        OIT_RoutineServices_Routine_31015400_Camera_EOL_Calibration_Start_RequestResults_RoutineServices_Routine_31015400_Camera5A023B1D: start-on-event=RoutineServices_Routine_31015400_Camera_EOL_Calibration_Start_RequestResults, operation=RoutineServices_Routine_31015400_Camera_EOL_Calibration_Start.RequestResults
        OIT_RoutineServices_Routine_31015400_Camera_EOL_Calibration_Start_Start_RoutineServices_Routine_31015400_Camera_EOL_CaliD5BE38B6: start-on-event=RoutineServices_Routine_31015400_Camera_EOL_Calibration_Start_Start, operation=RoutineServices_Routine_31015400_Camera_EOL_Calibration_Start.Start
        OIT_RoutineServices_Routine_3101D001_Disable_Fail_safe_reaction_Start_Stop_RoutineServices_Routine_3101D001_Disable_Fail2F69EAF9: start-on-event=RoutineServices_Routine_3101D001_Disable_Fail_safe_reaction_Start_Stop, operation=RoutineServices_Routine_3101D001_Disable_Fail_safe_reaction_Start.Stop
        OIT_RoutineServices_Routine_3101D001_Disable_Fail_safe_reaction_Start_Start_RoutineServices_Routine_3101D001_Disable_Fai3D5C2E21: start-on-event=RoutineServices_Routine_3101D001_Disable_Fail_safe_reaction_Start_Start, operation=RoutineServices_Routine_3101D001_Disable_Fail_safe_reaction_Start.Start
        OIT_RoutineServices_Routine_3101FE0E_Test_Pattern_Control_Start_Stop_RoutineServices_Routine_3101FE0E_Test_Pattern_ContrE8513346: start-on-event=RoutineServices_Routine_3101FE0E_Test_Pattern_Control_Start_Stop, operation=RoutineServices_Routine_3101FE0E_Test_Pattern_Control_Start.Stop
        OIT_RoutineServices_Routine_3101FE0E_Test_Pattern_Control_Start_Start_RoutineServices_Routine_3101FE0E_Test_Pattern_Cont02E14D23: start-on-event=RoutineServices_Routine_3101FE0E_Test_Pattern_Control_Start_Start, operation=RoutineServices_Routine_3101FE0E_Test_Pattern_Control_Start.Start
        OIT_RoutineServices_Routine_31015000_Park_Assist_ON_OFF_State_Start_Start_RoutineServices_Routine_31015000_Park_Assist_O8F767708: start-on-event=RoutineServices_Routine_31015000_Park_Assist_ON_OFF_State_Start_Start, operation=RoutineServices_Routine_31015000_Park_Assist_ON_OFF_State_Start.Start
        OIT_RoutineServices_Routine_31015101_Sensor_Functional_Test_Start_Start_RoutineServices_Routine_31015101_Sensor_Function13ED820E: start-on-event=RoutineServices_Routine_31015101_Sensor_Functional_Test_Start_Start, operation=RoutineServices_Routine_31015101_Sensor_Functional_Test_Start.Start
        OIT_RoutineServices_Routine_3101FF03_Test_Read_PMIC_Register_Start_Start_RoutineServices_Routine_3101FF03_Test_Read_PMIC2631FDF8: start-on-event=RoutineServices_Routine_3101FF03_Test_Read_PMIC_Register_Start_Start, operation=RoutineServices_Routine_3101FF03_Test_Read_PMIC_Register_Start.Start
        OIT_RoutineServices_Routine_31011000_USS_Debug_Signals_Enable_Disable_Start_Start_RoutineServices_Routine_31011000_USS_D9FD5E355: start-on-event=RoutineServices_Routine_31011000_USS_Debug_Signals_Enable_Disable_Start_Start, operation=RoutineServices_Routine_31011000_USS_Debug_Signals_Enable_Disable_Start.Start
        OIT_RoutineServices_Routine_31013000_XCP_Enable_Disable_Start_Start_RoutineServices_Routine_31013000_XCP_Enable_Disable_C573A1F8: start-on-event=RoutineServices_Routine_31013000_XCP_Enable_Disable_Start_Start, operation=RoutineServices_Routine_31013000_XCP_Enable_Disable_Start.Start
        OIT_RoutineServices_Routine_31012000_Original_VIN_Lock_Start_RoutineServices_Routine_31012000_Original_VIN_Lock_Start: start-on-event=RoutineServices_Routine_31012000_Original_VIN_Lock_Start, operation=RoutineServices_Routine_31012000_Original_VIN_Lock.Start
        OIT_RoutineServices_Routine_31012001_Original_VIN_Unlock_Start_RoutineServices_Routine_31012001_Original_VIN_Unlock_Start: start-on-event=RoutineServices_Routine_31012001_Original_VIN_Unlock_Start, operation=RoutineServices_Routine_31012001_Original_VIN_Unlock.Start
        OIT_RoutineServices_Routine_31015200_Plant_Mode_Routine_Start_RequestResults_RoutineServices_Routine_31015200_Plant_Mode9795A8F2: start-on-event=RoutineServices_Routine_31015200_Plant_Mode_Routine_Start_RequestResults, operation=RoutineServices_Routine_31015200_Plant_Mode_Routine_Start.RequestResults
        OIT_RoutineServices_Routine_31015200_Plant_Mode_Routine_Start_Start_RoutineServices_Routine_31015200_Plant_Mode_Routine_4849FA1C: start-on-event=RoutineServices_Routine_31015200_Plant_Mode_Routine_Start_Start, operation=RoutineServices_Routine_31015200_Plant_Mode_Routine_Start.Start
        OIT_RoutineServices_Routine_31015502_TRSC_Trailer_Calibration_Memory_Clear_Start_RequestResults_RoutineServices_Routine_7EF2C9E4: start-on-event=RoutineServices_Routine_31015502_TRSC_Trailer_Calibration_Memory_Clear_Start_RequestResults, operation=RoutineServices_Routine_31015502_TRSC_Trailer_Calibration_Memory_Clear_Start.RequestResults
        OIT_RoutineServices_Routine_31015502_TRSC_Trailer_Calibration_Memory_Clear_Start_Start_RoutineServices_Routine_31015502_0D41E251: start-on-event=RoutineServices_Routine_31015502_TRSC_Trailer_Calibration_Memory_Clear_Start_Start, operation=RoutineServices_Routine_31015502_TRSC_Trailer_Calibration_Memory_Clear_Start.Start
      per-instance-parameters:
        5 x parameter data prototype, all with sw-calibration-access=READ-WRITE:
          DID_5201_PlantModeStatus_DefaultValue: type=uint8, init-value=0
          VIN_CurrentVal_DefaultValue: type=VINlData_Arr, init-value=17 x 255
          VIN_Lock_DefaultValue: type=uint8, init-value=0
          VIN_OdometerCnt_DefaultValue: type=uint8, init-value=0
          VIN_OriginalVal_DefaultValue: type=VINlData_Arr, init-value=17 x 255
      port-api-options:
        enable-take-address=false, error-handling=NO-TRANSFORMER-ERROR-HANDLING, indirect-api=false, port=PpSnsrFnctnlTstFlg
        enable-take-address=false, error-handling=NO-TRANSFORMER-ERROR-HANDLING, indirect-api=false, port=RoutineServices_Routine_31015000_Park_Assist_ON_OFF_State_Start
        enable-take-address=false, error-handling=NO-TRANSFORMER-ERROR-HANDLING, indirect-api=false, port=RoutineServices_Routine_31015101_Sensor_Functional_Test_Start
        enable-take-address=false, error-handling=NO-TRANSFORMER-ERROR-HANDLING, indirect-api=false, port=RoutineServices_Routine_31015400_Camera_EOL_Calibration_Start
        enable-take-address=false, error-handling=NO-TRANSFORMER-ERROR-HANDLING, indirect-api=false, port=RoutineServices_Routine_31015401_Camera_Service_Calibration_Start
        enable-take-address=false, error-handling=NO-TRANSFORMER-ERROR-HANDLING, indirect-api=false, port=RoutineServices_Routine_3101D001_Disable_Fail_safe_reaction_Start
        enable-take-address=false, error-handling=NO-TRANSFORMER-ERROR-HANDLING, indirect-api=false, port=RoutineServices_Routine_3101D002_Check_Programming_Preconditions_Start
        enable-take-address=false, error-handling=NO-TRANSFORMER-ERROR-HANDLING, indirect-api=false, port=RoutineServices_Routine_3101FE02_Test_Write_PMIC_Register_Start
      24 x runnable:
        RE_RIDMgr_Main
          data-receive-point-by-arguments:
            23 x access:
              REC_RpSVSOutputToDiagMgr_TbSVS_e_SVSOutputToDiagMgrCamCalib_t: accessed-variable=RpSVSOutputToDiagMgr.TbSVS_e_SVSOutputToDiagMgrCamCalib_t
              REC_RpSVSToDiag_SVSToDiag_t: accessed-variable=RpSVSToDiag.SVSToDiag_t
              REC_RpTemperatureVal_GetTemperatureVal: accessed-variable=RpTemperatureVal.GetTemperatureVal
              REC_RpCalDataProviderNvmData_CalData_mcu1_0: accessed-variable=RpCalDataProviderNvmData.CalData_mcu1_0
              REC_RpToSwcSafeFD02Rx_CmdIgnSts: accessed-variable=RpToSwcSafeFD02Rx.CmdIgnSts
              REC_RpToSwcSafeFD02Rx_DriverDoorSts: accessed-variable=RpToSwcSafeFD02Rx.DriverDoorSts
              REC_RpToSwcSafeFD14Rx_FD14_VehicleSpeedVSOSig: accessed-variable=RpToSwcSafeFD14Rx.FD14_VehicleSpeedVSOSig
              REC_RpToSwcSafeFD02Rx_LHRDoorSts: accessed-variable=RpToSwcSafeFD02Rx.LHRDoorSts
              REC_RpToSwcSafeFD02Rx_PsngrDoorSts: accessed-variable=RpToSwcSafeFD02Rx.PsngrDoorSts
              REC_RpToSwcSafeFD02Rx_RHatchSts: accessed-variable=RpToSwcSafeFD02Rx.RHatchSts
              REC_RpToSwcSafeFD02Rx_RHRDoorSts: accessed-variable=RpToSwcSafeFD02Rx.RHRDoorSts
              REC_RpToSwcSafeFD02Rx_ShiftLeverPosition: accessed-variable=RpToSwcSafeFD02Rx.ShiftLeverPosition
              REC_RpToSwcFD02Rx_TotalOdometer: accessed-variable=RpToSwcFD02Rx.TotalOdometer
              REC_RpToSwcSafeFD14Rx_FD14_LwsAngle: accessed-variable=RpToSwcSafeFD14Rx.FD14_LwsAngle
              REC_RpToSwcSafeFD02Rx_VIN_DATA: accessed-variable=RpToSwcSafeFD02Rx.VIN_DATA
              REC_RpToSwcSafeFD02Rx_VIN_MSG: accessed-variable=RpToSwcSafeFD02Rx.VIN_MSG
              REC_RpToSwcSafeFD02Rx_GearEngaged: accessed-variable=RpToSwcSafeFD02Rx.GearEngaged
              REC_RpProxiToSWC_PRX_CanNod27_b: accessed-variable=RpProxiToSWC.PRX_CanNod27_b
              REC_RpToSwcSafeFD02Rx_ASCM_Stat: accessed-variable=RpToSwcSafeFD02Rx.ASCM_Stat
              REC_R_SSM_2_State_State_2_0: accessed-variable=R_SSM_2_State.State_2_0
              REC_R_SSM_2_State_State_2_1: accessed-variable=R_SSM_2_State.State_2_1
              REC_RpTrailerDetectOP_TrailerDetection_Output_DID_t: accessed-variable=RpTrailerDetectOP.TrailerDetection_Output_DID_t
              REC_RpProxiToSWC_SurroundViewCam_u8: accessed-variable=RpProxiToSWC.SurroundViewCam_u8
          data-send-points:
            10 x access:
              SEND_PpSnsrFnctnlTstFlg_SensorFunctionalTestFlag: accessed-variable=PpSnsrFnctnlTstFlg.SensorFunctionalTestFlag
              SEND_PpCan14DbgRoutineState_Can14DbgRoutineState_u8: accessed-variable=PpCan14DbgRoutineState.Can14DbgRoutine
              SEND_PpVINData_VINCurrentData: accessed-variable=PpVINData.VINCurrentData
              SEND_PpVINData_VINLockStatus: accessed-variable=PpVINData.VINLockStatus
              SEND_PpVINData_VINOdoCounter: accessed-variable=PpVINData.VINOdoCounter
              SEND_PpVINData_VINOriginalData: accessed-variable=PpVINData.VINOriginalData
              SEND_PpPlantMode_Status: accessed-variable=PpPlantMode.Status
              SEND_PpFailSafeReaction_State: accessed-variable=PpFailSafeReaction.State
              SEND_PpCalibRoutineTrigger_routine_b: accessed-variable=PpCalibRoutineTrigger.routine_b
              SEND_PpCalibRoutineType_value: accessed-variable=PpCalibRoutineType.value
          mode switch point SWITCH_PpModeProgPreconditionCheck_ModeProgPreconditionCheck: mode-group=PpModeProgPreconditionCheck.ModeProgPreconditionCheck
          30 x sync call:
            SC_RpReadVoltInfo_GetVoltageInfo: operation=RpReadVoltInfo.GetVoltageInfo
            SC_RpMCUDeviceRegReadWrit_MCUReadDeviceReg: operation=RpMCUDeviceRegReadWrit.MCUReadDeviceReg
            SC_RpMCUDeviceRegReadWrit_MCUReadDeviceRegData: operation=RpMCUDeviceRegReadWrit.MCUReadDeviceRegData
            SC_RpMCUDeviceRegReadWrit_MCUWriteDeviceReg: operation=RpMCUDeviceRegReadWrit.MCUWriteDeviceReg
            SC_RpIpcTxData_IPC_Write_v: operation=RpIpcTxData.IPC_Write_v
            SC_RpSVSCamCalibReset_WriteBlock: operation=RpSVSCamCalibReset.WriteBlock
            SC_NvMService_AC3_SRBS_DID_5201_PlantModeStatus_WriteBlock: operation=NvMService_AC3_SRBS_DID_5201_PlantModeStatus.WriteBlock
            SC_NvMService_AC3_SRBS_VIN_CurrentVal_WriteBlock: operation=NvMService_AC3_SRBS_VIN_CurrentVal.WriteBlock
            SC_NvMService_AC3_SRBS_VIN_Lock_WriteBlock: operation=NvMService_AC3_SRBS_VIN_Lock.WriteBlock
            SC_NvMService_AC3_SRBS_VIN_OriginalVal_WriteBlock: operation=NvMService_AC3_SRBS_VIN_OriginalVal.WriteBlock
            SC_RpError_CS_B_ReportErrorStatus1_0_B: operation=RpError_CS_B.ReportErrorStatus1_0_B
            SC_RpError_CS_QM_ReportErrorStatus1_0_QM: operation=RpError_CS_QM.ReportErrorStatus1_0_QM
            SC_NvMService_AC3_SRBS_VIN_OdometerCnt_SetRamBlockStatus: operation=NvMService_AC3_SRBS_VIN_OdometerCnt.SetRamBlockStatus
            SC_RpEventDTC_U026400_GetEventStatus: operation=RpEventDTC_U026400.GetEventStatus
            SC_RpEventDTC_B217A1C_GetEventStatus: operation=RpEventDTC_B217A1C.GetEventStatus
            SC_RpEventDTC_B217A92_GetEventStatus: operation=RpEventDTC_B217A92.GetEventStatus
            SC_RpEventDTC_B23C51C_GetEventStatus: operation=RpEventDTC_B23C51C.GetEventStatus
            SC_RpEventDTC_B23C592_GetEventStatus: operation=RpEventDTC_B23C592.GetEventStatus
            SC_RpEventDTC_B23C61C_GetEventStatus: operation=RpEventDTC_B23C61C.GetEventStatus
            SC_RpEventDTC_B23C692_GetEventStatus: operation=RpEventDTC_B23C692.GetEventStatus
            SC_RpEventDTC_B23C71C_GetEventStatus: operation=RpEventDTC_B23C71C.GetEventStatus
            SC_RpEventDTC_B23C792_GetEventStatus: operation=RpEventDTC_B23C792.GetEventStatus
            SC_RpEventDTC_U026500_GetEventStatus: operation=RpEventDTC_U026500.GetEventStatus
            SC_RpEventDTC_U026600_GetEventStatus: operation=RpEventDTC_U026600.GetEventStatus
            SC_RpEventDTC_U026700_GetEventStatus: operation=RpEventDTC_U026700.GetEventStatus
            SC_NvMService_AC3_SRBS_DID_5201_PlantModeStatus_GetErrorStatus: operation=NvMService_AC3_SRBS_DID_5201_PlantModeStatus.GetErrorStatus
            SC_NvMService_AC3_SRBS_VIN_CurrentVal_GetErrorStatus: operation=NvMService_AC3_SRBS_VIN_CurrentVal.GetErrorStatus
            SC_NvMService_AC3_SRBS_VIN_Lock_GetErrorStatus: operation=NvMService_AC3_SRBS_VIN_Lock.GetErrorStatus
            SC_NvMService_AC3_SRBS_VIN_OdometerCnt_GetErrorStatus: operation=NvMService_AC3_SRBS_VIN_OdometerCnt.GetErrorStatus
            SC_NvMService_AC3_SRBS_VIN_OriginalVal_GetErrorStatus: operation=NvMService_AC3_SRBS_VIN_OriginalVal.GetErrorStatus
        RE_RIDMgrr_Init  # Periodic Runnable of Satellite
        RoutineServices_Routine_31015401_Camera_Service_Calibration_Start_RequestResults
        RoutineServices_Routine_31015401_Camera_Service_Calibration_Start_Start
        RoutineServices_Routine_3101FE02_Test_Write_PMIC_Register_Start_Start
        RoutineServices_Routine_3101D002_Check_Programming_Preconditions_Start_Start
        RoutineServices_Routine_3101FE01_Calibration_Data_Reset_Start_Start
        RoutineServices_Routine_31015400_Camera_EOL_Calibration_Start_RequestResults
        RoutineServices_Routine_31015400_Camera_EOL_Calibration_Start_Start
        RoutineServices_Routine_3101D001_Disable_Fail_safe_reaction_Start_Stop
        RoutineServices_Routine_3101D001_Disable_Fail_safe_reaction_Start_Start
        RoutineServices_Routine_3101FE0E_Test_Pattern_Control_Start_Stop
        RoutineServices_Routine_3101FE0E_Test_Pattern_Control_Start_Start
        RoutineServices_Routine_31015000_Park_Assist_ON_OFF_State_Start_Start
        RoutineServices_Routine_31015101_Sensor_Functional_Test_Start_Start
        RoutineServices_Routine_3101FF03_Test_Read_PMIC_Register_Start_Start
        RoutineServices_Routine_31011000_USS_Debug_Signals_Enable_Disable_Start_Start
        RoutineServices_Routine_31013000_XCP_Enable_Disable_Start_Start
        RoutineServices_Routine_31012000_Original_VIN_Lock_Start
        RoutineServices_Routine_31012001_Original_VIN_Unlock_Start
        RoutineServices_Routine_31015200_Plant_Mode_Routine_Start_RequestResults
        RoutineServices_Routine_31015200_Plant_Mode_Routine_Start_Start
        RoutineServices_Routine_31015502_TRSC_Trailer_Calibration_Memory_Clear_Start_RequestResults
        RoutineServices_Routine_31015502_TRSC_Trailer_Calibration_Memory_Clear_Start_Start
      5 x swc service dependency, all with category=SERVICE:
        VIN_Lock: assigned-ports=role-based-port-assignment={port-prototype=NvMService_AC3_SRBS_VIN_Lock, role=NvMService_AC3_SRBS}
          assigned-datas:
            role=defaultValue, used-parameter-element=VIN_Lock_DefaultValue
            role=ramBlock, used-data-element=VIN_Lock_MirrorBlock
          service-needs:
            nv block needs VIN_Lock: n-data-sets=1, ram-block-status-control=API, reliability=NO-PROTECTION, restore-at-start=true, store-at-shutdown=false, store-immediate=true, write-verification=true
        VIN_OdometerCnt: assigned-ports=role-based-port-assignment={port-prototype=NvMService_AC3_SRBS_VIN_OdometerCnt, role=NvMService_AC3_SRBS}
          assigned-datas:
            role=ramBlock, used-data-element=VIN_OdometerCnt_MirrorBlock
            role=defaultValue, used-parameter-element=VIN_OdometerCnt_DefaultValue
          service-needs:
            nv block needs VIN_OdometerCnt: n-data-sets=1, ram-block-status-control=API, reliability=NO-PROTECTION, restore-at-start=true, store-at-shutdown=true
        VIN_OriginalVal: assigned-ports=role-based-port-assignment={port-prototype=NvMService_AC3_SRBS_VIN_OriginalVal, role=NvMService_AC3_SRBS}
          assigned-datas:
            role=ramBlock, used-data-element=VIN_OriginalVal_MirrorBlock
            role=defaultValue, used-parameter-element=VIN_OriginalVal_DefaultValue
          service-needs:
            nv block needs VIN_OriginalVal: n-data-sets=1, ram-block-status-control=API, reliability=NO-PROTECTION, restore-at-start=true, store-at-shutdown=false, store-immediate=true, write-verification=true
        VIN_CurrentVal: assigned-ports=role-based-port-assignment={port-prototype=NvMService_AC3_SRBS_VIN_CurrentVal, role=NvMService_AC3_SRBS}
          assigned-datas:
            role=ramBlock, used-data-element=VIN_CurrentVal_MirrorBlock
            role=defaultValue, used-parameter-element=VIN_CurrentVal_DefaultValue
          service-needs:
            nv block needs VIN_CurrentVal: n-data-sets=1, ram-block-status-control=API, reliability=NO-PROTECTION, restore-at-start=true, store-at-shutdown=false, store-immediate=true, write-verification=true
        DID_5201_PlantModeStatus: assigned-ports=role-based-port-assignment={port-prototype=NvMService_AC3_SRBS_DID_5201_PlantModeStatus, role=NvMService_AC3_SRBS}
          assigned-datas:
            role=ramBlock, used-data-element=DID_5201_PlantModeStatus_MirrorBlock
            role=defaultValue, used-parameter-element=DID_5201_PlantModeStatus_DefaultValue
          service-needs:
            nv block needs DID_5201_PlantModeStatus: n-data-sets=1, ram-block-status-control=API, reliability=NO-PROTECTION, restore-at-start=true, store-at-shutdown=false, store-immediate=true, write-verification=true
  swc implementation SWC_RIDMgr_Implementation: programming-language=C, vendor-id=0, behavior=SWC_RIDMgr_InternalBehavior
    code-descriptors:
      code Default: artifact-descriptors=autosar-engineering-object=category=SWSRC
